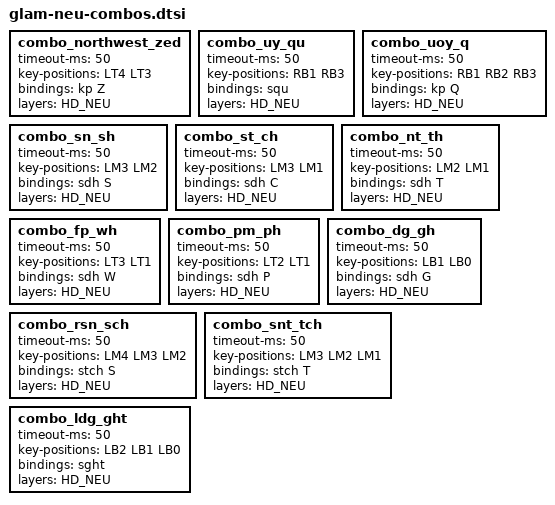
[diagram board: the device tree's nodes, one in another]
/*
 * Copyright (c) 2024 Allister MacLeod
 *
 * SPDX-License-Identifier: MIT
 */

// Shared combos for multigraphs in Hands Down Neu. This file must be
// included *after* the line where the HD_NEU layer symbol is defined in
// the keymap.

// W F M P V     # . ' " J
// R S N T B     , A E I H
// X C L D G     - U O Y K

// Not sure this ASCII art representation of 2-key combos makes sense. :)

// W -z-   F      M -ph- P      V     # .     '     " -Bks- J
//  1       2      3      4      5   6 7     8     9      0
// R -Ctl- S -sh- N -th- T      B     , A -{- E -}- I -Ent- H
//                                                                     :)
// X -Shf- C      L      D -gh- G     - U -(- O -)- Y -Shf- K

// This file is meant to be included in the middle of a `combos` block.

// combos {

  // Upper left two keys for Z in Hands Down.
  combo_northwest_zed {
    timeout-ms = <50>;
    key-positions = <LT4 LT3>;
    bindings = <&kp Z>;
    layers = <HD_NEU>;
  };
  // Combo U and Y to produce Qu in Hands Down.
  combo_uy_qu {
    timeout-ms = <50>;
    key-positions = <RB1 RB3>;
    bindings = <&squ>;
    layers = <HD_NEU>;
  };
  // Combo U, O, and Y to produce bare Q in Hands Down.
  combo_uoy_q {
    timeout-ms = <50>;
    key-positions = <RB1 RB2 RB3>;
    bindings = <&kp Q>;
    layers = <HD_NEU>;
  };
  // Combos for H digraphs in Hands Down.
  combo_sn_sh {
    timeout-ms = <50>;
    key-positions = <LM3 LM2>;
    bindings = <&sdh S>;
    layers = <HD_NEU>;
  };
  combo_st_ch {
    timeout-ms = <50>;
    key-positions = <LM3 LM1>;
    bindings = <&sdh C>;
    layers = <HD_NEU>;
  };
  combo_nt_th {
    timeout-ms = <50>;
    key-positions = <LM2 LM1>;
    bindings = <&sdh T>;
    layers = <HD_NEU>;
  };
  combo_fp_wh {
    timeout-ms = <50>;
    key-positions = <LT3 LT1>;
    bindings = <&sdh W>;
    layers = <HD_NEU>;
  };
  combo_pm_ph {
    timeout-ms = <50>;
    key-positions = <LT2 LT1>;
    bindings = <&sdh P>;
    layers = <HD_NEU>;
  };
  combo_dg_gh {
    timeout-ms = <50>;
    key-positions = <LB1 LB0>;
    bindings = <&sdh G>;
    layers = <HD_NEU>;
  };
  // Combos for trigraphs and 3-letter consonant clusters.
  combo_rsn_sch {
    timeout-ms = <50>;
    key-positions = <LM4 LM3 LM2>;
    bindings = <&stch S>;
    layers = <HD_NEU>;
  };
  combo_snt_tch {
    timeout-ms = <50>;
    key-positions = <LM3 LM2 LM1>;
    bindings = <&stch T>;
    layers = <HD_NEU>;
  };
  combo_ldg_ght {
    timeout-ms = <50>;
    key-positions = <LB2 LB1 LB0>;
    bindings = <&sght>;
    layers = <HD_NEU>;
  };

// };
